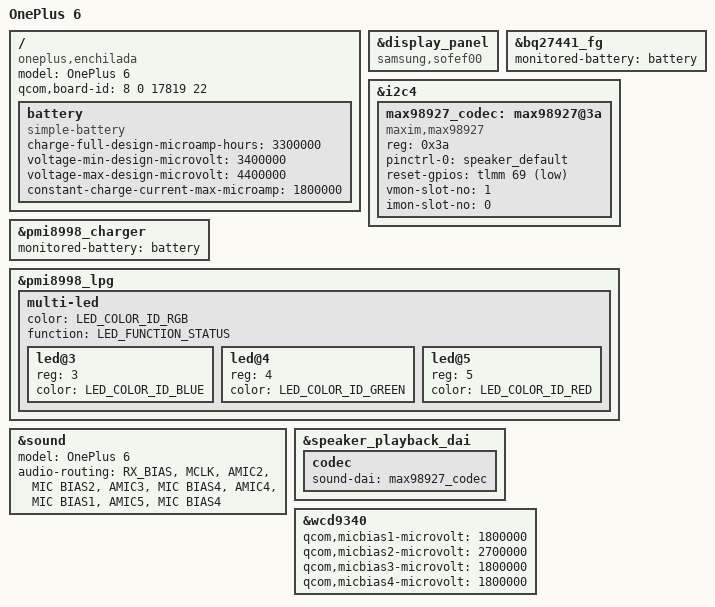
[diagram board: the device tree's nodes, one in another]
// SPDX-License-Identifier: GPL-2.0
/*
 * SDM845 OnePlus 6 (enchilada) device tree.
 *
 * Copyright (c) 2020, The Linux Foundation. All rights reserved.
 */

#include <dt-bindings/leds/common.h>
#include "sdm845-oneplus-common.dtsi"

/ {
	model = "OnePlus 6";
	compatible = "oneplus,enchilada", "qcom,sdm845";
	qcom,board-id = <8 0 17819 22>;

	battery: battery {
		compatible = "simple-battery";

		charge-full-design-microamp-hours = <3300000>;
		voltage-min-design-microvolt = <3400000>;
		voltage-max-design-microvolt = <4400000>;

		/*
		 * Typical designs have multiple charger ICs which can handle more
		 * current but the OnePlus 6/T do not, hence the lower limit. This
		 * does not apply when using the Dash Charger, however this is not
		 * yet supported.
		 */
		constant-charge-current-max-microamp = <1800000>;
	};
};

&display_panel {
	status = "okay";

	compatible = "samsung,sofef00";
};

&bq27441_fg {
	monitored-battery = <&battery>;
};

&i2c4 {
	status = "okay";

	max98927_codec: max98927@3a {
		compatible = "maxim,max98927";
		reg = <0x3a>;
		#sound-dai-cells = <0>;

		pinctrl-0 = <&speaker_default>;
		pinctrl-names = "default";

		reset-gpios = <&tlmm 69 GPIO_ACTIVE_LOW>;

		vmon-slot-no = <1>;
		imon-slot-no = <0>;
	};
};

&pmi8998_charger {
	monitored-battery = <&battery>;
};

&pmi8998_lpg {
	status = "okay";

	multi-led {
		color = <LED_COLOR_ID_RGB>;
		function = LED_FUNCTION_STATUS;

		#address-cells = <1>;
		#size-cells = <0>;

		led@3 {
			reg = <3>;
			color = <LED_COLOR_ID_BLUE>;
		};

		led@4 {
			reg = <4>;
			color = <LED_COLOR_ID_GREEN>;
		};

		led@5 {
			reg = <5>;
			color = <LED_COLOR_ID_RED>;
		};
	};
};

&sound {
	model = "OnePlus 6";
	audio-routing = "RX_BIAS", "MCLK",
			"AMIC2", "MIC BIAS2",
			"AMIC3", "MIC BIAS4",
			"AMIC4", "MIC BIAS1",
			"AMIC5", "MIC BIAS4";
};

&speaker_playback_dai {
	codec {
		sound-dai = <&max98927_codec>;
	};
};

&wcd9340 {
	qcom,micbias1-microvolt = <1800000>;
	qcom,micbias2-microvolt = <2700000>;
	qcom,micbias3-microvolt = <1800000>;
	qcom,micbias4-microvolt = <1800000>;
};
